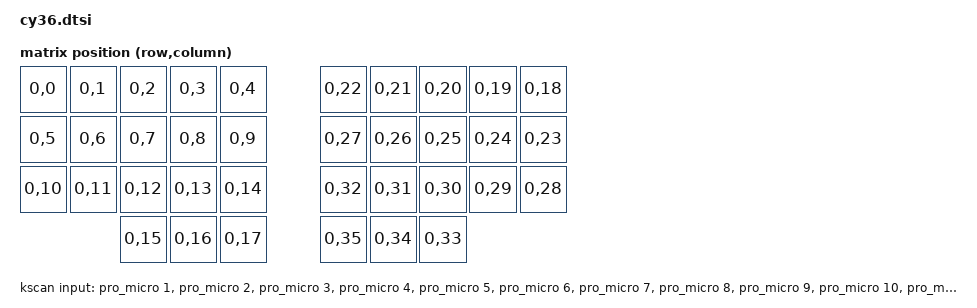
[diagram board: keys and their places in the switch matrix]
// This file was generated from a template. Edit it to match your keyboard.
// See https://zmk.dev/docs/development/hardware-integration/new-shield for more
// instructions.

#include <dt-bindings/zmk/matrix_transform.h>

#include "cy36-layouts.dtsi"

/ {
    chosen {
        zmk,physical-layout = &default_layout;
    };

    default_transform: default_transform {
        // See https://zmk.dev/docs/development/hardware-integration/new-shield#matrix-transform
        // for how to configure this
        compatible = "zmk,matrix-transform";
        columns = <36>;
        rows = <1>;
        map = <
            RC(0, 0)  RC(0, 1)  RC(0, 2)  RC(0, 3)  RC(0, 4)      RC(0, 22) RC(0, 21) RC(0, 20) RC(0, 19) RC(0, 18)
            RC(0, 5)  RC(0, 6)  RC(0, 7)  RC(0, 8)  RC(0, 9)      RC(0, 27) RC(0, 26) RC(0, 25) RC(0, 24) RC(0, 23)
            RC(0, 10) RC(0, 11) RC(0, 12) RC(0, 13) RC(0, 14)     RC(0, 32) RC(0, 31) RC(0, 30) RC(0, 29) RC(0, 28)
                                RC(0, 15) RC(0, 16) RC(0, 17)     RC(0, 35) RC(0, 34) RC(0, 33)
        >;
    };

    kscan: kscan {
        // If the hardware does not use a switch matrix, change this to the
        // appropriate driver and update the properties below to match.
        // See https://zmk.dev/docs/config/kscan for supported key scan drivers.
        compatible = "zmk,kscan-gpio-direct";
        // Set this to "col2row" or "row2col" to match the hardware. If using
        // "row2col", change the col-gpios in the _left.overlay and _right.overlay
        // files to (GPIO_ACTIVE_HIGH | GPIO_PULL_DOWN) and the row-gpios here to
        // GPIO_ACTIVE_HIGH.
        wakeup-source;
        // toggle-mode;

        input-gpios
        = <&pro_micro  1 (GPIO_ACTIVE_LOW | GPIO_PULL_UP)>
        , <&pro_micro  2 (GPIO_ACTIVE_LOW | GPIO_PULL_UP)>
        , <&pro_micro  3 (GPIO_ACTIVE_LOW | GPIO_PULL_UP)>
        , <&pro_micro  4 (GPIO_ACTIVE_LOW | GPIO_PULL_UP)>
        , <&pro_micro  5 (GPIO_ACTIVE_LOW | GPIO_PULL_UP)>
        , <&pro_micro  6 (GPIO_ACTIVE_LOW | GPIO_PULL_UP)>
        , <&pro_micro  7 (GPIO_ACTIVE_LOW | GPIO_PULL_UP)>
        , <&pro_micro  8 (GPIO_ACTIVE_LOW | GPIO_PULL_UP)>
        , <&pro_micro  9 (GPIO_ACTIVE_LOW | GPIO_PULL_UP)>
        , <&pro_micro 10 (GPIO_ACTIVE_LOW | GPIO_PULL_UP)>
        , <&pro_micro 11 (GPIO_ACTIVE_LOW | GPIO_PULL_UP)>
        , <&pro_micro 12 (GPIO_ACTIVE_LOW | GPIO_PULL_UP)>
        , <&pro_micro 13 (GPIO_ACTIVE_LOW | GPIO_PULL_UP)>
        , <&pro_micro 14 (GPIO_ACTIVE_LOW | GPIO_PULL_UP)>
        , <&pro_micro 15 (GPIO_ACTIVE_LOW | GPIO_PULL_UP)>
        , <&pro_micro 16 (GPIO_ACTIVE_LOW | GPIO_PULL_UP)>
        , <&pro_micro 17 (GPIO_ACTIVE_LOW | GPIO_PULL_UP)>
        , <&pro_micro 18 (GPIO_ACTIVE_LOW | GPIO_PULL_UP)>
        ;

        // See https://zmk.dev/docs/development/hardware-integration/new-shield#shield-overlays
    };

};
